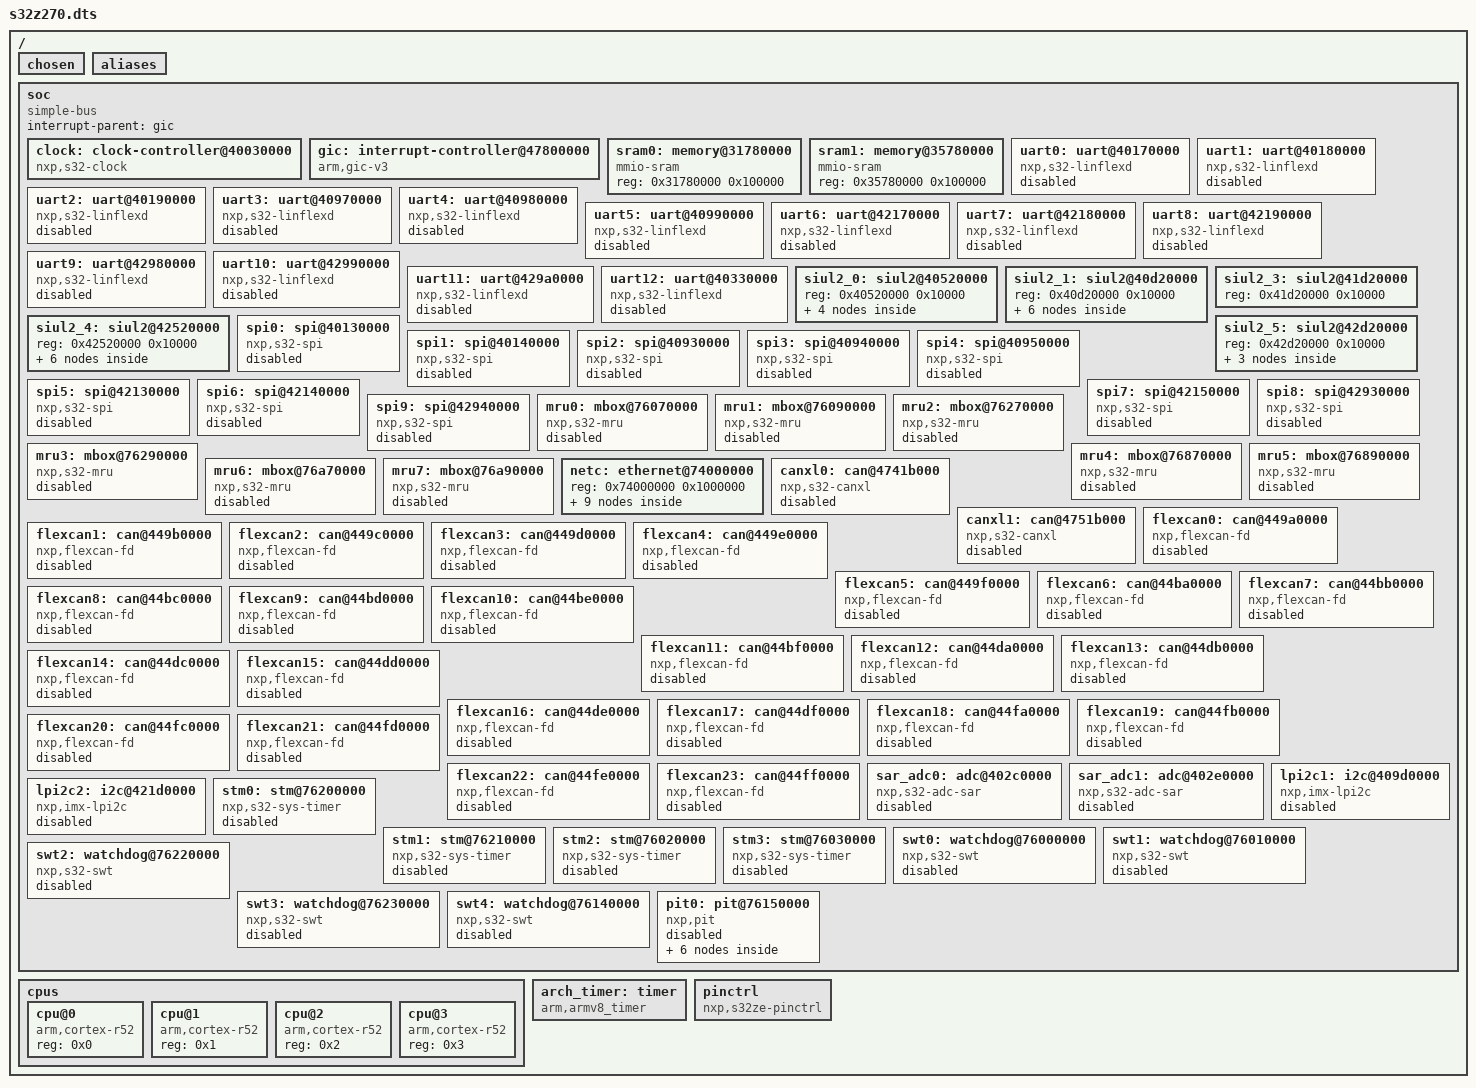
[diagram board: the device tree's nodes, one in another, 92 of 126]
/dts-v1/;

/ {
	#address-cells = < 0x1 >;
	#size-cells = < 0x1 >;
	chosen {
	};
	aliases {
	};
	soc {
		#address-cells = < 0x1 >;
		#size-cells = < 0x1 >;
		compatible = "simple-bus";
		ranges;
		interrupt-parent = < &gic >;
		clock: clock-controller@40030000 {
			compatible = "nxp,s32-clock";
			reg = < 0x40030000 0x10000 >, < 0x40200000 0x10000 >, < 0x40210000 0x10000 >, < 0x40220000 0x10000 >, < 0x40260000 0x10000 >, < 0x40270000 0x10000 >, < 0x40830000 0x10000 >, < 0x41030000 0x10000 >, < 0x41830000 0x10000 >, < 0x42030000 0x10000 >, < 0x42830000 0x10000 >, < 0x44030000 0x10000 >, < 0x440a0000 0x10000 >;
			#clock-cells = < 0x1 >;
			status = "okay";
			phandle = < 0x6 >;
		};
		gic: interrupt-controller@47800000 {
			compatible = "arm,gic-v3", "arm,gic";
			reg = < 0x47800000 0x10000 >, < 0x47900000 0x80000 >;
			interrupt-controller;
			#interrupt-cells = < 0x4 >;
			status = "okay";
			phandle = < 0x1 >;
		};
		sram0: memory@31780000 {
			compatible = "mmio-sram";
			reg = < 0x31780000 0x100000 >;
		};
		sram1: memory@35780000 {
			compatible = "mmio-sram";
			reg = < 0x35780000 0x100000 >;
		};
		uart0: uart@40170000 {
			compatible = "nxp,s32-linflexd";
			reg = < 0x40170000 0x1000 >;
			interrupts = < 0x0 0xd4 0x2 0xa0 >;
			status = "disabled";
		};
		uart1: uart@40180000 {
			compatible = "nxp,s32-linflexd";
			reg = < 0x40180000 0x1000 >;
			interrupts = < 0x0 0xd5 0x2 0xa0 >;
			status = "disabled";
		};
		uart2: uart@40190000 {
			compatible = "nxp,s32-linflexd";
			reg = < 0x40190000 0x1000 >;
			interrupts = < 0x0 0xd6 0x2 0xa0 >;
			status = "disabled";
		};
		uart3: uart@40970000 {
			compatible = "nxp,s32-linflexd";
			reg = < 0x40970000 0x1000 >;
			interrupts = < 0x0 0xd7 0x2 0xa0 >;
			status = "disabled";
		};
		uart4: uart@40980000 {
			compatible = "nxp,s32-linflexd";
			reg = < 0x40980000 0x1000 >;
			interrupts = < 0x0 0xd8 0x2 0xa0 >;
			status = "disabled";
		};
		uart5: uart@40990000 {
			compatible = "nxp,s32-linflexd";
			reg = < 0x40990000 0x1000 >;
			interrupts = < 0x0 0xd9 0x2 0xa0 >;
			status = "disabled";
		};
		uart6: uart@42170000 {
			compatible = "nxp,s32-linflexd";
			reg = < 0x42170000 0x1000 >;
			interrupts = < 0x0 0xda 0x2 0xa0 >;
			status = "disabled";
		};
		uart7: uart@42180000 {
			compatible = "nxp,s32-linflexd";
			reg = < 0x42180000 0x1000 >;
			interrupts = < 0x0 0xdb 0x2 0xa0 >;
			status = "disabled";
		};
		uart8: uart@42190000 {
			compatible = "nxp,s32-linflexd";
			reg = < 0x42190000 0x1000 >;
			interrupts = < 0x0 0xdc 0x2 0xa0 >;
			status = "disabled";
		};
		uart9: uart@42980000 {
			compatible = "nxp,s32-linflexd";
			reg = < 0x42980000 0x1000 >;
			interrupts = < 0x0 0xdd 0x2 0xa0 >;
			status = "disabled";
		};
		uart10: uart@42990000 {
			compatible = "nxp,s32-linflexd";
			reg = < 0x42990000 0x1000 >;
			interrupts = < 0x0 0xde 0x2 0xa0 >;
			status = "disabled";
		};
		uart11: uart@429a0000 {
			compatible = "nxp,s32-linflexd";
			reg = < 0x429a0000 0x1000 >;
			interrupts = < 0x0 0xdf 0x2 0xa0 >;
			status = "disabled";
		};
		uart12: uart@40330000 {
			compatible = "nxp,s32-linflexd";
			reg = < 0x40330000 0x1000 >;
			interrupts = < 0x0 0xcd 0x2 0xa0 >;
			status = "disabled";
		};
		siul2_0: siul2@40520000 {
			reg = < 0x40520000 0x10000 >;
			#address-cells = < 0x1 >;
			#size-cells = < 0x1 >;
			eirq0: eirq0@40520010 {
				compatible = "nxp,s32-siul2-eirq";
				reg = < 0x40520010 0xb4 >;
				interrupts = < 0x0 0x202 0x2 0xa0 >;
				interrupt-controller;
				#interrupt-cells = < 0x2 >;
				status = "disabled";
				phandle = < 0x2 >;
			};
			gpioa: gpio@40521702 {
				compatible = "nxp,s32-gpio";
				reg = < 0x40521702 0x2 >, < 0x40520240 0x40 >;
				reg-names = "pgpdo", "mscr";
				interrupt-parent = < &eirq0 >;
				interrupts = < 0x1 0x1 >, < 0x3 0x0 >, < 0x5 0x2 >, < 0xc 0x3 >, < 0xd 0x4 >, < 0xe 0x5 >, < 0xf 0x6 >;
				gpio-controller;
				#gpio-cells = < 0x2 >;
				ngpios = < 0x10 >;
				status = "disabled";
			};
			gpiob: gpio@40521700 {
				compatible = "nxp,s32-gpio";
				reg = < 0x40521700 0x2 >, < 0x40520280 0x40 >;
				reg-names = "pgpdo", "mscr";
				interrupt-parent = < &eirq0 >;
				interrupts = < 0x0 0x7 >;
				gpio-controller;
				#gpio-cells = < 0x2 >;
				ngpios = < 0xf >;
				status = "disabled";
			};
			gpioo: gpio@40521716 {
				compatible = "nxp,s32-gpio";
				reg = < 0x40521716 0x2 >, < 0x405204c0 0x40 >;
				reg-names = "pgpdo", "mscr";
				gpio-controller;
				#gpio-cells = < 0x2 >;
				ngpios = < 0xe >;
				gpio-reserved-ranges = < 0x0 0xa >;
				status = "disabled";
			};
		};
		siul2_1: siul2@40d20000 {
			reg = < 0x40d20000 0x10000 >;
			#address-cells = < 0x1 >;
			#size-cells = < 0x1 >;
			eirq1: eirq1@40d20010 {
				compatible = "nxp,s32-siul2-eirq";
				reg = < 0x40d20010 0xb4 >;
				interrupts = < 0x0 0x203 0x2 0xa0 >;
				interrupt-controller;
				#interrupt-cells = < 0x2 >;
				status = "disabled";
				phandle = < 0x3 >;
			};
			gpioc: gpio@40d21700 {
				compatible = "nxp,s32-gpio";
				reg = < 0x40d21700 0x2 >, < 0x40d20280 0x40 >;
				reg-names = "pgpdo", "mscr";
				interrupt-parent = < &eirq1 >;
				interrupts = < 0x3 0x0 >, < 0x5 0x1 >;
				gpio-controller;
				#gpio-cells = < 0x2 >;
				ngpios = < 0x10 >;
				gpio-reserved-ranges = < 0x0 0xf >;
				status = "disabled";
			};
			gpiod: gpio@40d21706 {
				compatible = "nxp,s32-gpio";
				reg = < 0x40d21706 0x2 >, < 0x40d202c0 0x40 >;
				reg-names = "pgpdo", "mscr";
				gpio-controller;
				#gpio-cells = < 0x2 >;
				ngpios = < 0x10 >;
				status = "disabled";
			};
			gpioe: gpio@40d21704 {
				compatible = "nxp,s32-gpio";
				reg = < 0x40d21704 0x2 >, < 0x40d20300 0x40 >;
				reg-names = "pgpdo", "mscr";
				gpio-controller;
				#gpio-cells = < 0x2 >;
				ngpios = < 0x10 >;
				status = "disabled";
			};
			gpiof: gpio@40d2170a {
				compatible = "nxp,s32-gpio";
				reg = < 0x40d2170a 0x2 >, < 0x40d20340 0x40 >;
				reg-names = "pgpdo", "mscr";
				gpio-controller;
				#gpio-cells = < 0x2 >;
				ngpios = < 0x10 >;
				status = "disabled";
			};
			gpiog: gpio@40d21708 {
				compatible = "nxp,s32-gpio";
				reg = < 0x40d21708 0x2 >, < 0x40d20380 0x40 >;
				reg-names = "pgpdo", "mscr";
				interrupt-parent = < &eirq1 >;
				interrupts = < 0x0 0x2 >, < 0x1 0x3 >, < 0x4 0x4 >, < 0x5 0x5 >, < 0xa 0x6 >, < 0xb 0x7 >;
				gpio-controller;
				#gpio-cells = < 0x2 >;
				ngpios = < 0xc >;
				status = "disabled";
			};
		};
		siul2_3: siul2@41d20000 {
			reg = < 0x41d20000 0x10000 >;
		};
		siul2_4: siul2@42520000 {
			reg = < 0x42520000 0x10000 >;
			#address-cells = < 0x1 >;
			#size-cells = < 0x1 >;
			eirq4: eirq4@42520010 {
				compatible = "nxp,s32-siul2-eirq";
				reg = < 0x42520010 0xb4 >;
				interrupts = < 0x0 0x204 0x2 0xa0 >;
				interrupt-controller;
				#interrupt-cells = < 0x2 >;
				status = "disabled";
				phandle = < 0x4 >;
			};
			gpioh: gpio@42521708 {
				compatible = "nxp,s32-gpio";
				reg = < 0x42521708 0x2 >, < 0x42520380 0x40 >;
				reg-names = "pgpdo", "mscr";
				gpio-controller;
				#gpio-cells = < 0x2 >;
				ngpios = < 0x10 >;
				gpio-reserved-ranges = < 0x0 0xc >;
				status = "disabled";
			};
			gpioi: gpio@4252170e {
				compatible = "nxp,s32-gpio";
				reg = < 0x4252170e 0x2 >, < 0x425203c0 0x40 >;
				reg-names = "pgpdo", "mscr";
				interrupt-parent = < &eirq4 >;
				interrupts = < 0xb 0x0 >, < 0xd 0x1 >;
				gpio-controller;
				#gpio-cells = < 0x2 >;
				ngpios = < 0x10 >;
				status = "disabled";
			};
			gpioj: gpio@4252170c {
				compatible = "nxp,s32-gpio";
				reg = < 0x4252170c 0x2 >, < 0x42520400 0x40 >;
				reg-names = "pgpdo", "mscr";
				interrupt-parent = < &eirq4 >;
				interrupts = < 0xc 0x2 >;
				gpio-controller;
				#gpio-cells = < 0x2 >;
				ngpios = < 0x10 >;
				status = "disabled";
			};
			gpiok: gpio@42521712 {
				compatible = "nxp,s32-gpio";
				reg = < 0x42521712 0x2 >, < 0x42520440 0x40 >;
				reg-names = "pgpdo", "mscr";
				interrupt-parent = < &eirq4 >;
				interrupts = < 0x4 0x3 >, < 0x6 0x4 >, < 0x9 0x5 >, < 0xb 0x6 >, < 0xd 0x7 >;
				gpio-controller;
				#gpio-cells = < 0x2 >;
				ngpios = < 0x10 >;
				status = "disabled";
			};
			gpiol: gpio@42521710 {
				compatible = "nxp,s32-gpio";
				reg = < 0x42521710 0x2 >, < 0x42520480 0x40 >;
				reg-names = "pgpdo", "mscr";
				gpio-controller;
				#gpio-cells = < 0x2 >;
				ngpios = < 0x2 >;
				status = "disabled";
			};
		};
		siul2_5: siul2@42d20000 {
			reg = < 0x42d20000 0x10000 >;
			#address-cells = < 0x1 >;
			#size-cells = < 0x1 >;
			eirq5: eirq5@42d20010 {
				compatible = "nxp,s32-siul2-eirq";
				reg = < 0x42d20010 0xb4 >;
				interrupts = < 0x0 0x205 0x2 0xa0 >;
				interrupt-controller;
				#interrupt-cells = < 0x2 >;
				status = "disabled";
				phandle = < 0x5 >;
			};
			gpiom: gpio@42d21710 {
				compatible = "nxp,s32-gpio";
				reg = < 0x42d21710 0x2 >, < 0x42d20480 0x40 >;
				reg-names = "pgpdo", "mscr";
				interrupt-parent = < &eirq5 >;
				interrupts = < 0x1 0x0 >, < 0x3 0x1 >, < 0x5 0x2 >, < 0x7 0x3 >;
				gpio-controller;
				#gpio-cells = < 0x2 >;
				ngpios = < 0x10 >;
				gpio-reserved-ranges = < 0x0 0x2 >;
				status = "disabled";
			};
			gpion: gpio@42d21716 {
				compatible = "nxp,s32-gpio";
				reg = < 0x42d21716 0x2 >, < 0x42d204c0 0x40 >;
				reg-names = "pgpdo", "mscr";
				interrupt-parent = < &eirq5 >;
				interrupts = < 0x0 0x4 >, < 0x2 0x5 >, < 0x5 0x6 >, < 0x6 0x7 >;
				gpio-controller;
				#gpio-cells = < 0x2 >;
				ngpios = < 0xa >;
				status = "disabled";
			};
		};
		spi0: spi@40130000 {
			compatible = "nxp,s32-spi";
			reg = < 0x40130000 0x10000 >;
			interrupts = < 0x0 0xbf 0x2 0xa0 >;
			clocks = < &clock 0x110 >;
			num-cs = < 0x5 >;
			#address-cells = < 0x1 >;
			#size-cells = < 0x0 >;
			status = "disabled";
		};
		spi1: spi@40140000 {
			compatible = "nxp,s32-spi";
			reg = < 0x40140000 0x10000 >;
			interrupts = < 0x0 0xc0 0x2 0xa0 >;
			clocks = < &clock 0x111 >;
			num-cs = < 0x5 >;
			#address-cells = < 0x1 >;
			#size-cells = < 0x0 >;
			status = "disabled";
		};
		spi2: spi@40930000 {
			compatible = "nxp,s32-spi";
			reg = < 0x40930000 0x10000 >;
			interrupts = < 0x0 0xc1 0x2 0xa0 >;
			clocks = < &clock 0x113 >;
			num-cs = < 0x5 >;
			#address-cells = < 0x1 >;
			#size-cells = < 0x0 >;
			status = "disabled";
		};
		spi3: spi@40940000 {
			compatible = "nxp,s32-spi";
			reg = < 0x40940000 0x10000 >;
			interrupts = < 0x0 0xc2 0x2 0xa0 >;
			clocks = < &clock 0x114 >;
			num-cs = < 0x5 >;
			#address-cells = < 0x1 >;
			#size-cells = < 0x0 >;
			status = "disabled";
		};
		spi4: spi@40950000 {
			compatible = "nxp,s32-spi";
			reg = < 0x40950000 0x10000 >;
			interrupts = < 0x0 0xc3 0x2 0xa0 >;
			clocks = < &clock 0x115 >;
			num-cs = < 0x5 >;
			#address-cells = < 0x1 >;
			#size-cells = < 0x0 >;
			status = "disabled";
		};
		spi5: spi@42130000 {
			compatible = "nxp,s32-spi";
			reg = < 0x42130000 0x10000 >;
			interrupts = < 0x0 0xc4 0x2 0xa0 >;
			clocks = < &clock 0x117 >;
			num-cs = < 0x5 >;
			#address-cells = < 0x1 >;
			#size-cells = < 0x0 >;
			status = "disabled";
		};
		spi6: spi@42140000 {
			compatible = "nxp,s32-spi";
			reg = < 0x42140000 0x10000 >;
			interrupts = < 0x0 0xc5 0x2 0xa0 >;
			clocks = < &clock 0x118 >;
			num-cs = < 0x5 >;
			#address-cells = < 0x1 >;
			#size-cells = < 0x0 >;
			status = "disabled";
		};
		spi7: spi@42150000 {
			compatible = "nxp,s32-spi";
			reg = < 0x42150000 0x10000 >;
			interrupts = < 0x0 0xc6 0x2 0xa0 >;
			clocks = < &clock 0x119 >;
			num-cs = < 0x5 >;
			#address-cells = < 0x1 >;
			#size-cells = < 0x0 >;
			status = "disabled";
		};
		spi8: spi@42930000 {
			compatible = "nxp,s32-spi";
			reg = < 0x42930000 0x10000 >;
			interrupts = < 0x0 0xc7 0x2 0xa0 >;
			clocks = < &clock 0x11b >;
			num-cs = < 0x5 >;
			#address-cells = < 0x1 >;
			#size-cells = < 0x0 >;
			status = "disabled";
		};
		spi9: spi@42940000 {
			compatible = "nxp,s32-spi";
			reg = < 0x42940000 0x10000 >;
			interrupts = < 0x0 0xc8 0x2 0xa0 >;
			clocks = < &clock 0x11c >;
			num-cs = < 0x5 >;
			#address-cells = < 0x1 >;
			#size-cells = < 0x0 >;
			status = "disabled";
		};
		mru0: mbox@76070000 {
			compatible = "nxp,s32-mru";
			reg = < 0x76070000 0x10000 >;
			interrupts = < 0x1 0x1 0x2 0xa0 >;
			#mbox-cells = < 0x1 >;
			status = "disabled";
		};
		mru1: mbox@76090000 {
			compatible = "nxp,s32-mru";
			reg = < 0x76090000 0x10000 >;
			interrupts = < 0x1 0x1 0x2 0xa0 >;
			#mbox-cells = < 0x1 >;
			status = "disabled";
		};
		mru2: mbox@76270000 {
			compatible = "nxp,s32-mru";
			reg = < 0x76270000 0x10000 >;
			interrupts = < 0x1 0x1 0x2 0xa0 >;
			#mbox-cells = < 0x1 >;
			status = "disabled";
		};
		mru3: mbox@76290000 {
			compatible = "nxp,s32-mru";
			reg = < 0x76290000 0x10000 >;
			interrupts = < 0x1 0x1 0x2 0xa0 >;
			#mbox-cells = < 0x1 >;
			status = "disabled";
		};
		mru4: mbox@76870000 {
			compatible = "nxp,s32-mru";
			reg = < 0x76870000 0x10000 >;
			interrupts = < 0x1 0x1 0x2 0xa0 >;
			#mbox-cells = < 0x1 >;
			status = "disabled";
		};
		mru5: mbox@76890000 {
			compatible = "nxp,s32-mru";
			reg = < 0x76890000 0x10000 >;
			interrupts = < 0x1 0x1 0x2 0xa0 >;
			#mbox-cells = < 0x1 >;
			status = "disabled";
		};
		mru6: mbox@76a70000 {
			compatible = "nxp,s32-mru";
			reg = < 0x76a70000 0x10000 >;
			interrupts = < 0x1 0x1 0x2 0xa0 >;
			#mbox-cells = < 0x1 >;
			status = "disabled";
		};
		mru7: mbox@76a90000 {
			compatible = "nxp,s32-mru";
			reg = < 0x76a90000 0x10000 >;
			interrupts = < 0x1 0x1 0x2 0xa0 >;
			#mbox-cells = < 0x1 >;
			status = "disabled";
		};
		netc: ethernet@74000000 {
			reg = < 0x74000000 0x1000000 >;
			#address-cells = < 0x1 >;
			#size-cells = < 0x1 >;
			ranges;
			emdio: mdio@74b60000 {
				compatible = "nxp,s32-netc-emdio";
				reg = < 0x74b60000 0x1c44 >;
				status = "disabled";
				#address-cells = < 0x1 >;
				#size-cells = < 0x0 >;
			};
			enetc_psi0: ethernet@74b00000 {
				compatible = "nxp,s32-netc-psi";
				reg = < 0x74b00000 0x10000 >;
				status = "disabled";
			};
			enetc_vsi1: ethernet@74bc0000 {
				compatible = "nxp,s32-netc-vsi";
				reg = < 0x74bc0000 0x10000 >;
				status = "disabled";
			};
			enetc_vsi2: ethernet@74bd0000 {
				compatible = "nxp,s32-netc-vsi";
				reg = < 0x74bd0000 0x10000 >;
				status = "disabled";
			};
			enetc_vsi3: ethernet@74be0000 {
				compatible = "nxp,s32-netc-vsi";
				reg = < 0x74be0000 0x10000 >;
				status = "disabled";
			};
			enetc_vsi4: ethernet@74bf0000 {
				compatible = "nxp,s32-netc-vsi";
				reg = < 0x74bf0000 0x10000 >;
				status = "disabled";
			};
			enetc_vsi5: ethernet@74c00000 {
				compatible = "nxp,s32-netc-vsi";
				reg = < 0x74c00000 0x10000 >;
				status = "disabled";
			};
			enetc_vsi6: ethernet@74c10000 {
				compatible = "nxp,s32-netc-vsi";
				reg = < 0x74c10000 0x10000 >;
				status = "disabled";
			};
			enetc_vsi7: ethernet@74c20000 {
				compatible = "nxp,s32-netc-vsi";
				reg = < 0x74c20000 0x10000 >;
				status = "disabled";
			};
		};
		canxl0: can@4741b000 {
			compatible = "nxp,s32-canxl";
			reg = < 0x4741b000 0x1000 >, < 0x47423000 0x1000 >, < 0x47425000 0x1000 >, < 0x47427000 0x1000 >;
			reg-names = "sic", "rx_fifo", "rx_fifo_ctrl", "mru";
			status = "disabled";
			interrupts = < 0x0 0xe0 0x2 0xa0 >, < 0x0 0xe1 0x2 0xb0 >;
			interrupt-names = "rx_tx_mru", "error";
			clocks = < &clock 0xe7 >;
		};
		canxl1: can@4751b000 {
			compatible = "nxp,s32-canxl";
			reg = < 0x4751b000 0x1000 >, < 0x47523000 0x1000 >, < 0x47525000 0x1000 >, < 0x47527000 0x1000 >;
			reg-names = "sic", "rx_fifo", "rx_fifo_ctrl", "mru";
			status = "disabled";
			interrupts = < 0x0 0xe2 0x2 0xa0 >, < 0x0 0xe3 0x2 0xb0 >;
			interrupt-names = "rx_tx_mru", "error";
			clocks = < &clock 0xe7 >;
		};
		flexcan0: can@449a0000 {
			compatible = "nxp,flexcan-fd", "nxp,flexcan";
			reg = < 0x449a0000 0x4000 >;
			clk-source = < 0x0 >;
			interrupts = < 0x0 0x245 0x2 0xa0 >, < 0x0 0x247 0x2 0xa0 >, < 0x0 0x248 0x2 0xa0 >, < 0x0 0x249 0x2 0xa0 >, < 0x0 0x24a 0x2 0xa0 >;
			interrupt-names = "ored", "ored_0_31_mb", "ored_32_63_mb", "ored_64_95_mb", "ored_96_127_mb";
			clocks = < &clock 0x64 >;
			status = "disabled";
		};
		flexcan1: can@449b0000 {
			compatible = "nxp,flexcan-fd", "nxp,flexcan";
			reg = < 0x449b0000 0x4000 >;
			clk-source = < 0x0 >;
			interrupts = < 0x0 0x24b 0x2 0xa0 >, < 0x0 0x24d 0x2 0xa0 >, < 0x0 0x24e 0x2 0xa0 >, < 0x0 0x24f 0x2 0xa0 >, < 0x0 0x250 0x2 0xa0 >;
			interrupt-names = "ored", "ored_0_31_mb", "ored_32_63_mb", "ored_64_95_mb", "ored_96_127_mb";
			clocks = < &clock 0x64 >;
			status = "disabled";
		};
		flexcan2: can@449c0000 {
			compatible = "nxp,flexcan-fd", "nxp,flexcan";
			clk-source = < 0x0 >;
			reg = < 0x449c0000 0x4000 >;
			interrupts = < 0x0 0x251 0x2 0xa0 >, < 0x0 0x253 0x2 0xa0 >, < 0x0 0x254 0x2 0xa0 >, < 0x0 0x255 0x2 0xa0 >, < 0x0 0x256 0x2 0xa0 >;
			interrupt-names = "ored", "ored_0_31_mb", "ored_32_63_mb", "ored_64_95_mb", "ored_96_127_mb";
			clocks = < &clock 0x64 >;
			status = "disabled";
		};
		flexcan3: can@449d0000 {
			compatible = "nxp,flexcan-fd", "nxp,flexcan";
			clk-source = < 0x0 >;
			reg = < 0x449d0000 0x4000 >;
			interrupts = < 0x0 0x257 0x2 0xa0 >, < 0x0 0x259 0x2 0xa0 >, < 0x0 0x25a 0x2 0xa0 >, < 0x0 0x25b 0x2 0xa0 >, < 0x0 0x25c 0x2 0xa0 >;
			interrupt-names = "ored", "ored_0_31_mb", "ored_32_63_mb", "ored_64_95_mb", "ored_96_127_mb";
			clocks = < &clock 0x64 >;
			status = "disabled";
		};
		flexcan4: can@449e0000 {
			compatible = "nxp,flexcan-fd", "nxp,flexcan";
			clk-source = < 0x0 >;
			reg = < 0x449e0000 0x4000 >;
			interrupts = < 0x0 0x25d 0x2 0xa0 >, < 0x0 0x25f 0x2 0xa0 >, < 0x0 0x260 0x2 0xa0 >, < 0x0 0x261 0x2 0xa0 >, < 0x0 0x262 0x2 0xa0 >;
			interrupt-names = "ored", "ored_0_31_mb", "ored_32_63_mb", "ored_64_95_mb", "ored_96_127_mb";
			clocks = < &clock 0x64 >;
			status = "disabled";
		};
		flexcan5: can@449f0000 {
			compatible = "nxp,flexcan-fd", "nxp,flexcan";
			clk-source = < 0x0 >;
			reg = < 0x449f0000 0x4000 >;
			interrupts = < 0x0 0x263 0x2 0xa0 >, < 0x0 0x265 0x2 0xa0 >, < 0x0 0x266 0x2 0xa0 >, < 0x0 0x267 0x2 0xa0 >, < 0x0 0x268 0x2 0xa0 >;
			interrupt-names = "ored", "ored_0_31_mb", "ored_32_63_mb", "ored_64_95_mb", "ored_96_127_mb";
			clocks = < &clock 0x64 >;
			status = "disabled";
		};
		flexcan6: can@44ba0000 {
			compatible = "nxp,flexcan-fd", "nxp,flexcan";
			clk-source = < 0x0 >;
			reg = < 0x44ba0000 0x4000 >;
			interrupts = < 0x0 0x269 0x2 0xa0 >, < 0x0 0x26b 0x2 0xa0 >, < 0x0 0x26c 0x2 0xa0 >, < 0x0 0x26d 0x2 0xa0 >, < 0x0 0x26e 0x2 0xa0 >;
			interrupt-names = "ored", "ored_0_31_mb", "ored_32_63_mb", "ored_64_95_mb", "ored_96_127_mb";
			clocks = < &clock 0x64 >;
			status = "disabled";
		};
		flexcan7: can@44bb0000 {
			compatible = "nxp,flexcan-fd", "nxp,flexcan";
			clk-source = < 0x0 >;
			reg = < 0x44bb0000 0x4000 >;
			interrupts = < 0x0 0x26f 0x2 0xa0 >, < 0x0 0x271 0x2 0xa0 >, < 0x0 0x272 0x2 0xa0 >, < 0x0 0x273 0x2 0xa0 >, < 0x0 0x274 0x2 0xa0 >;
			interrupt-names = "ored", "ored_0_31_mb", "ored_32_63_mb", "ored_64_95_mb", "ored_96_127_mb";
			clocks = < &clock 0x64 >;
			status = "disabled";
		};
		flexcan8: can@44bc0000 {
			compatible = "nxp,flexcan-fd", "nxp,flexcan";
			clk-source = < 0x0 >;
			reg = < 0x44bc0000 0x4000 >;
			interrupts = < 0x0 0x275 0x2 0xa0 >, < 0x0 0x277 0x2 0xa0 >, < 0x0 0x278 0x2 0xa0 >, < 0x0 0x279 0x2 0xa0 >, < 0x0 0x27a 0x2 0xa0 >;
			interrupt-names = "ored", "ored_0_31_mb", "ored_32_63_mb", "ored_64_95_mb", "ored_96_127_mb";
			clocks = < &clock 0x64 >;
			status = "disabled";
		};
		flexcan9: can@44bd0000 {
			compatible = "nxp,flexcan-fd", "nxp,flexcan";
			clk-source = < 0x0 >;
			reg = < 0x44bd0000 0x4000 >;
			interrupts = < 0x0 0x27b 0x2 0xa0 >, < 0x0 0x27d 0x2 0xa0 >, < 0x0 0x27e 0x2 0xa0 >, < 0x0 0x27f 0x2 0xa0 >, < 0x0 0x280 0x2 0xa0 >;
			interrupt-names = "ored", "ored_0_31_mb", "ored_32_63_mb", "ored_64_95_mb", "ored_96_127_mb";
			clocks = < &clock 0x64 >;
			status = "disabled";
		};
		flexcan10: can@44be0000 {
			compatible = "nxp,flexcan-fd", "nxp,flexcan";
			clk-source = < 0x0 >;
			reg = < 0x44be0000 0x4000 >;
			interrupts = < 0x0 0x281 0x2 0xa0 >, < 0x0 0x283 0x2 0xa0 >, < 0x0 0x284 0x2 0xa0 >, < 0x0 0x285 0x2 0xa0 >, < 0x0 0x286 0x2 0xa0 >;
			interrupt-names = "ored", "ored_0_31_mb", "ored_32_63_mb", "ored_64_95_mb", "ored_96_127_mb";
			clocks = < &clock 0x64 >;
			status = "disabled";
		};
		flexcan11: can@44bf0000 {
			compatible = "nxp,flexcan-fd", "nxp,flexcan";
			clk-source = < 0x0 >;
			reg = < 0x44bf0000 0x4000 >;
			interrupts = < 0x0 0x287 0x2 0xa0 >, < 0x0 0x289 0x2 0xa0 >, < 0x0 0x28a 0x2 0xa0 >, < 0x0 0x28b 0x2 0xa0 >, < 0x0 0x28c 0x2 0xa0 >;
			interrupt-names = "ored", "ored_0_31_mb", "ored_32_63_mb", "ored_64_95_mb", "ored_96_127_mb";
			clocks = < &clock 0x64 >;
			status = "disabled";
		};
		flexcan12: can@44da0000 {
			compatible = "nxp,flexcan-fd", "nxp,flexcan";
			clk-source = < 0x0 >;
			reg = < 0x44da0000 0x4000 >;
			interrupts = < 0x0 0x28d 0x2 0xa0 >, < 0x0 0x28f 0x2 0xa0 >, < 0x0 0x290 0x2 0xa0 >, < 0x0 0x291 0x2 0xa0 >, < 0x0 0x292 0x2 0xa0 >;
			interrupt-names = "ored", "ored_0_31_mb", "ored_32_63_mb", "ored_64_95_mb", "ored_96_127_mb";
			clocks = < &clock 0x64 >;
			status = "disabled";
		};
		flexcan13: can@44db0000 {
			compatible = "nxp,flexcan-fd", "nxp,flexcan";
			clk-source = < 0x0 >;
			reg = < 0x44db0000 0x4000 >;
			interrupts = < 0x0 0x293 0x2 0xa0 >, < 0x0 0x295 0x2 0xa0 >, < 0x0 0x296 0x2 0xa0 >, < 0x0 0x297 0x2 0xa0 >, < 0x0 0x298 0x2 0xa0 >;
			interrupt-names = "ored", "ored_0_31_mb", "ored_32_63_mb", "ored_64_95_mb", "ored_96_127_mb";
			clocks = < &clock 0x64 >;
			status = "disabled";
		};
		flexcan14: can@44dc0000 {
			compatible = "nxp,flexcan-fd", "nxp,flexcan";
			clk-source = < 0x0 >;
			reg = < 0x44dc0000 0x4000 >;
			interrupts = < 0x0 0x299 0x2 0xa0 >, < 0x0 0x29b 0x2 0xa0 >, < 0x0 0x29c 0x2 0xa0 >, < 0x0 0x29d 0x2 0xa0 >, < 0x0 0x29e 0x2 0xa0 >;
			interrupt-names = "ored", "ored_0_31_mb", "ored_32_63_mb", "ored_64_95_mb", "ored_96_127_mb";
			clocks = < &clock 0x64 >;
			status = "disabled";
		};
		flexcan15: can@44dd0000 {
			compatible = "nxp,flexcan-fd", "nxp,flexcan";
			clk-source = < 0x0 >;
			reg = < 0x44dd0000 0x4000 >;
			interrupts = < 0x0 0x29f 0x2 0xa0 >, < 0x0 0x2a1 0x2 0xa0 >, < 0x0 0x2a2 0x2 0xa0 >, < 0x0 0x2a3 0x2 0xa0 >, < 0x0 0x2a4 0x2 0xa0 >;
			interrupt-names = "ored", "ored_0_31_mb", "ored_32_63_mb", "ored_64_95_mb", "ored_96_127_mb";
			clocks = < &clock 0x64 >;
			status = "disabled";
		};
		flexcan16: can@44de0000 {
			compatible = "nxp,flexcan-fd", "nxp,flexcan";
			clk-source = < 0x0 >;
			reg = < 0x44de0000 0x4000 >;
			interrupts = < 0x0 0x2a5 0x2 0xa0 >, < 0x0 0x2a7 0x2 0xa0 >, < 0x0 0x2a8 0x2 0xa0 >, < 0x0 0x2a9 0x2 0xa0 >, < 0x0 0x2aa 0x2 0xa0 >;
			interrupt-names = "ored", "ored_0_31_mb", "ored_32_63_mb", "ored_64_95_mb", "ored_96_127_mb";
			clocks = < &clock 0x64 >;
			status = "disabled";
		};
		flexcan17: can@44df0000 {
			compatible = "nxp,flexcan-fd", "nxp,flexcan";
			clk-source = < 0x0 >;
			reg = < 0x44df0000 0x4000 >;
			interrupts = < 0x0 0x2ab 0x2 0xa0 >, < 0x0 0x2ad 0x2 0xa0 >, < 0x0 0x2ae 0x2 0xa0 >, < 0x0 0x2af 0x2 0xa0 >, < 0x0 0x2b0 0x2 0xa0 >;
			interrupt-names = "ored", "ored_0_31_mb", "ored_32_63_mb", "ored_64_95_mb", "ored_96_127_mb";
			clocks = < &clock 0x64 >;
			status = "disabled";
		};
		flexcan18: can@44fa0000 {
			compatible = "nxp,flexcan-fd", "nxp,flexcan";
			clk-source = < 0x0 >;
			reg = < 0x44fa0000 0x4000 >;
			interrupts = < 0x0 0x2b1 0x2 0xa0 >, < 0x0 0x2b3 0x2 0xa0 >, < 0x0 0x2b4 0x2 0xa0 >, < 0x0 0x2b5 0x2 0xa0 >, < 0x0 0x2b6 0x2 0xa0 >;
			interrupt-names = "ored", "ored_0_31_mb", "ored_32_63_mb", "ored_64_95_mb", "ored_96_127_mb";
			clocks = < &clock 0x64 >;
			status = "disabled";
		};
		flexcan19: can@44fb0000 {
			compatible = "nxp,flexcan-fd", "nxp,flexcan";
			clk-source = < 0x0 >;
			reg = < 0x44fb0000 0x4000 >;
			interrupts = < 0x0 0x2b7 0x2 0xa0 >, < 0x0 0x2b9 0x2 0xa0 >, < 0x0 0x2ba 0x2 0xa0 >, < 0x0 0x2bb 0x2 0xa0 >, < 0x0 0x2bc 0x2 0xa0 >;
			interrupt-names = "ored", "ored_0_31_mb", "ored_32_63_mb", "ored_64_95_mb", "ored_96_127_mb";
			clocks = < &clock 0x64 >;
			status = "disabled";
		};
		flexcan20: can@44fc0000 {
			compatible = "nxp,flexcan-fd", "nxp,flexcan";
			clk-source = < 0x0 >;
			reg = < 0x44fc0000 0x4000 >;
			interrupts = < 0x0 0x2bd 0x2 0xa0 >, < 0x0 0x2bf 0x2 0xa0 >, < 0x0 0x2c0 0x2 0xa0 >, < 0x0 0x2c1 0x2 0xa0 >, < 0x0 0x2c2 0x2 0xa0 >;
			interrupt-names = "ored", "ored_0_31_mb", "ored_32_63_mb", "ored_64_95_mb", "ored_96_127_mb";
			clocks = < &clock 0x64 >;
			status = "disabled";
		};
		flexcan21: can@44fd0000 {
			compatible = "nxp,flexcan-fd", "nxp,flexcan";
			clk-source = < 0x0 >;
			reg = < 0x44fd0000 0x4000 >;
			interrupts = < 0x0 0x2c3 0x2 0xa0 >, < 0x0 0x2c5 0x2 0xa0 >, < 0x0 0x2c6 0x2 0xa0 >, < 0x0 0x2c7 0x2 0xa0 >, < 0x0 0x2c8 0x2 0xa0 >;
			interrupt-names = "ored", "ored_0_31_mb", "ored_32_63_mb", "ored_64_95_mb", "ored_96_127_mb";
			clocks = < &clock 0x64 >;
			status = "disabled";
		};
		flexcan22: can@44fe0000 {
			compatible = "nxp,flexcan-fd", "nxp,flexcan";
			clk-source = < 0x0 >;
			reg = < 0x44fe0000 0x4000 >;
			interrupts = < 0x0 0x2c9 0x2 0xa0 >, < 0x0 0x2cb 0x2 0xa0 >, < 0x0 0x2cc 0x2 0xa0 >, < 0x0 0x2cd 0x2 0xa0 >, < 0x0 0x2ce 0x2 0xa0 >;
			interrupt-names = "ored", "ored_0_31_mb", "ored_32_63_mb", "ored_64_95_mb", "ored_96_127_mb";
			clocks = < &clock 0x64 >;
			status = "disabled";
		};
		flexcan23: can@44ff0000 {
			compatible = "nxp,flexcan-fd", "nxp,flexcan";
			clk-source = < 0x0 >;
			reg = < 0x44ff0000 0x4000 >;
			interrupts = < 0x0 0x2cf 0x2 0xa0 >, < 0x0 0x2d1 0x2 0xa0 >, < 0x0 0x2d2 0x2 0xa0 >, < 0x0 0x2d3 0x2 0xa0 >, < 0x0 0x2d4 0x2 0xa0 >;
			interrupt-names = "ored", "ored_0_31_mb", "ored_32_63_mb", "ored_64_95_mb", "ored_96_127_mb";
			clocks = < &clock 0x64 >;
			status = "disabled";
		};
		sar_adc0: adc@402c0000 {
			compatible = "nxp,s32-adc-sar";
			reg = < 0x402c0000 0x1000 >;
			interrupts = < 0x0 0xa8 0x2 0xa0 >, < 0x0 0xa9 0x2 0xa0 >, < 0x0 0xaa 0x2 0xa0 >;
			#io-channel-cells = < 0x1 >;
			status = "disabled";
		};
		sar_adc1: adc@402e0000 {
			compatible = "nxp,s32-adc-sar";
			reg = < 0x402e0000 0x1000 >;
			interrupts = < 0x0 0xc9 0x2 0xa0 >, < 0x0 0xca 0x2 0xa0 >, < 0x0 0xcb 0x2 0xa0 >;
			#io-channel-cells = < 0x1 >;
			status = "disabled";
		};
		lpi2c1: i2c@409d0000 {
			compatible = "nxp,imx-lpi2c";
			reg = < 0x409d0000 0x10000 >;
			#address-cells = < 0x1 >;
			#size-cells = < 0x0 >;
			interrupts = < 0x0 0xfd 0x2 0xa0 >;
			clocks = < &clock 0xc2 >;
			clock-frequency = < 0x186a0 >;
			status = "disabled";
		};
		lpi2c2: i2c@421d0000 {
			compatible = "nxp,imx-lpi2c";
			reg = < 0x421d0000 0x10000 >;
			#address-cells = < 0x1 >;
			#size-cells = < 0x0 >;
			interrupts = < 0x0 0xfe 0x2 0xa0 >;
			clocks = < &clock 0xe2 >;
			clock-frequency = < 0x186a0 >;
			status = "disabled";
		};
		stm0: stm@76200000 {
			compatible = "nxp,s32-sys-timer";
			reg = < 0x76200000 0x10000 >;
			interrupts = < 0x0 0xd 0x2 0xa0 >;
			clocks = < &clock 0xfe >;
			status = "disabled";
		};
		stm1: stm@76210000 {
			compatible = "nxp,s32-sys-timer";
			reg = < 0x76210000 0x10000 >;
			interrupts = < 0x0 0xe 0x2 0xa0 >;
			clocks = < &clock 0xfe >;
			status = "disabled";
		};
		stm2: stm@76020000 {
			compatible = "nxp,s32-sys-timer";
			reg = < 0x76020000 0x10000 >;
			interrupts = < 0x0 0xf 0x2 0xa0 >;
			clocks = < &clock 0xfe >;
			status = "disabled";
		};
		stm3: stm@76030000 {
			compatible = "nxp,s32-sys-timer";
			reg = < 0x76030000 0x10000 >;
			interrupts = < 0x0 0x10 0x2 0xa0 >;
			clocks = < &clock 0xfe >;
			status = "disabled";
		};
		swt0: watchdog@76000000 {
			compatible = "nxp,s32-swt";
			reg = < 0x76000000 0x10000 >;
			interrupts = < 0x0 0x8 0x2 0xa0 >;
			clocks = < &clock 0x1 >;
			service-mode = "fixed";
			status = "disabled";
		};
		swt1: watchdog@76010000 {
			compatible = "nxp,s32-swt";
			reg = < 0x76010000 0x10000 >;
			interrupts = < 0x0 0x9 0x2 0xa0 >;
			clocks = < &clock 0x1 >;
			service-mode = "fixed";
			status = "disabled";
		};
		swt2: watchdog@76220000 {
			compatible = "nxp,s32-swt";
			reg = < 0x76220000 0x10000 >;
			interrupts = < 0x0 0xa 0x2 0xa0 >;
			clocks = < &clock 0x1 >;
			service-mode = "fixed";
			status = "disabled";
		};
		swt3: watchdog@76230000 {
			compatible = "nxp,s32-swt";
			reg = < 0x76230000 0x10000 >;
			interrupts = < 0x0 0xb 0x2 0xa0 >;
			clocks = < &clock 0x1 >;
			service-mode = "fixed";
			status = "disabled";
		};
		swt4: watchdog@76140000 {
			compatible = "nxp,s32-swt";
			reg = < 0x76140000 0x10000 >;
			interrupts = < 0x0 0xc 0x2 0xa0 >;
			clocks = < &clock 0x1 >;
			service-mode = "fixed";
			status = "disabled";
		};
		pit0: pit@76150000 {
			compatible = "nxp,pit";
			reg = < 0x76150000 0x10000 >;
			interrupts = < 0x0 0x13 0x2 0xa0 >;
			clocks = < &clock 0xae >;
			max-load-value = < 0xffffff >;
			status = "disabled";
			#address-cells = < 0x1 >;
			#size-cells = < 0x0 >;
			pit0_channel0: pit0_channel@0 {
				compatible = "nxp,pit-channel";
				reg = < 0x0 >;
				status = "disabled";
			};
			pit0_channel1: pit0_channel@1 {
				compatible = "nxp,pit-channel";
				reg = < 0x1 >;
				status = "disabled";
			};
			pit0_channel2: pit0_channel@2 {
				compatible = "nxp,pit-channel";
				reg = < 0x2 >;
				status = "disabled";
			};
			pit0_channel3: pit0_channel@3 {
				compatible = "nxp,pit-channel";
				reg = < 0x3 >;
				status = "disabled";
			};
			pit0_channel4: pit0_channel@4 {
				compatible = "nxp,pit-channel";
				reg = < 0x4 >;
				status = "disabled";
			};
			pit0_channel5: pit0_channel@5 {
				compatible = "nxp,pit-channel";
				reg = < 0x5 >;
				status = "disabled";
			};
		};
	};
	cpus {
		#address-cells = < 0x1 >;
		#size-cells = < 0x0 >;
		cpu@0 {
			device_type = "cpu";
			compatible = "arm,cortex-r52";
			reg = < 0x0 >;
		};
		cpu@1 {
			device_type = "cpu";
			compatible = "arm,cortex-r52";
			reg = < 0x1 >;
		};
		cpu@2 {
			device_type = "cpu";
			compatible = "arm,cortex-r52";
			reg = < 0x2 >;
		};
		cpu@3 {
			device_type = "cpu";
			compatible = "arm,cortex-r52";
			reg = < 0x3 >;
		};
	};
	arch_timer: timer {
		compatible = "arm,armv8_timer";
		interrupts = < 0x1 0xd 0x2 0xa0 >, < 0x1 0xe 0x2 0xa0 >, < 0x1 0xb 0x2 0xa0 >, < 0x1 0xa 0x2 0xa0 >;
		interrupt-parent = < &gic >;
	};
	pinctrl: pinctrl {
		compatible = "nxp,s32ze-pinctrl";
		status = "okay";
	};
};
